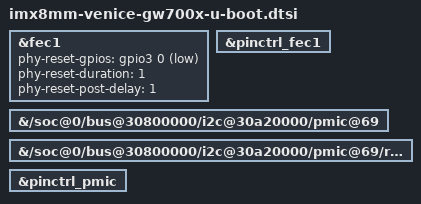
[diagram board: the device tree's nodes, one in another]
// SPDX-License-Identifier: GPL-2.0+
/*
 * Copyright 2021 Gateworks Corporation
 */

#include "imx8mm-venice-u-boot.dtsi"

&fec1 {
	phy-reset-gpios = <&gpio3 0 GPIO_ACTIVE_LOW>;
	phy-reset-duration = <1>;
	phy-reset-post-delay = <1>;
};

&pinctrl_fec1 {
	u-boot,dm-spl;
};

&{/soc@0/bus@30800000/i2c@30a20000/pmic@69} {
	u-boot,dm-spl;
};

&{/soc@0/bus@30800000/i2c@30a20000/pmic@69/regulators} {
	u-boot,dm-spl;
};

&pinctrl_pmic {
	u-boot,dm-spl;
};
